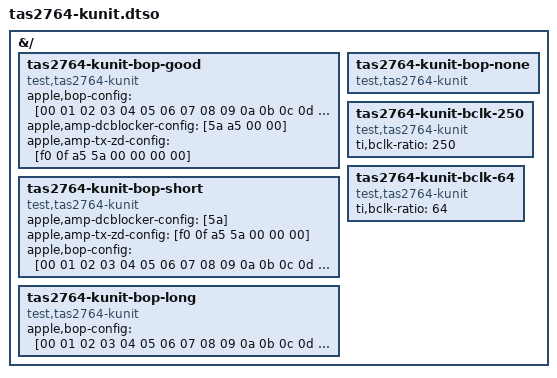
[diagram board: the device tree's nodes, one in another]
// SPDX-License-Identifier: GPL-2.0-only
/*
 * Nodes for the TAS2764 KUnit tests (tas2764-bop-test.h and
 * tas2764-bclk-ratio-test.h). The values are made up; only their length
 * and placement matter.
 */
/dts-v1/;
/plugin/;

&{/} {
	tas2764-kunit-bop-good {
		compatible = "test,tas2764-kunit";
		apple,bop-config = [00 01 02 03 04 05 06 07 08 09 0a 0b
				    0c 0d 0e 0f 10 11 12 13 14 15 16 17];
		apple,amp-dcblocker-config = [5a a5 00 00];
		apple,amp-tx-zd-config = [f0 0f a5 5a 00 00 00 00];
	};

	tas2764-kunit-bop-short {
		compatible = "test,tas2764-kunit";
		apple,amp-dcblocker-config = [5a];
		apple,amp-tx-zd-config = [f0 0f a5 5a 00 00 00];
		apple,bop-config = [00 01 02 03 04 05 06 07 08 09 0a 0b
				    0c 0d 0e 0f 10 11 12 13 14 15 16];
	};

	tas2764-kunit-bop-long {
		compatible = "test,tas2764-kunit";
		apple,bop-config = [00 01 02 03 04 05 06 07 08 09 0a 0b
				    0c 0d 0e 0f 10 11 12 13 14 15 16 17 18];
	};

	tas2764-kunit-bop-none {
		compatible = "test,tas2764-kunit";
	};

	/* tas2764-bclk-ratio-test.h */
	tas2764-kunit-bclk-250 {
		compatible = "test,tas2764-kunit";
		ti,bclk-ratio = <250>;
	};

	tas2764-kunit-bclk-64 {
		compatible = "test,tas2764-kunit";
		ti,bclk-ratio = <64>;
	};
};
